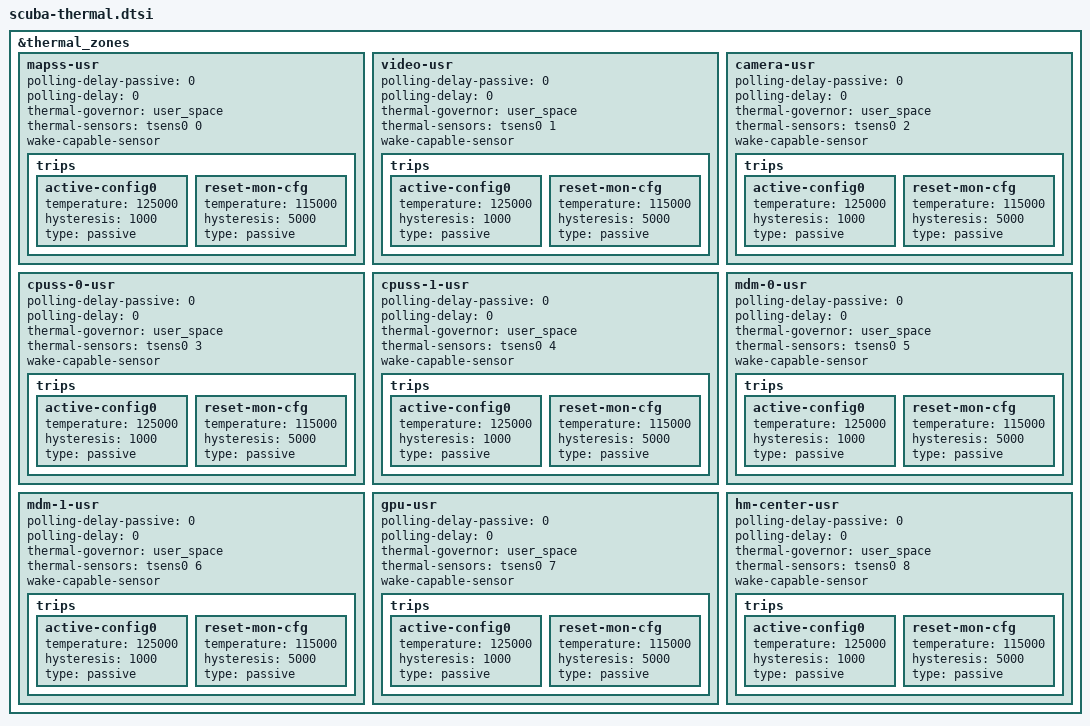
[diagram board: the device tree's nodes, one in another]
# include <dt-bindings/thermal/thermal.h>

&thermal_zones {
	mapss-usr {
		polling-delay-passive = <0>;
		polling-delay = <0>;
		thermal-governor = "user_space";
		thermal-sensors = <&tsens0 0>;
		wake-capable-sensor;
		trips {
			active-config0 {
				temperature = <125000>;
				hysteresis = <1000>;
				type = "passive";
			};

			reset-mon-cfg {
				temperature = <115000>;
				hysteresis = <5000>;
				type = "passive";
			};
		};
	};

	video-usr {
		polling-delay-passive = <0>;
		polling-delay = <0>;
		thermal-governor = "user_space";
		thermal-sensors = <&tsens0 1>;
		wake-capable-sensor;
		trips {
			active-config0 {
				temperature = <125000>;
				hysteresis = <1000>;
				type = "passive";
			};

			reset-mon-cfg {
				temperature = <115000>;
				hysteresis = <5000>;
				type = "passive";
			};
		};
	};

	camera-usr {
		polling-delay-passive = <0>;
		polling-delay = <0>;
		thermal-governor = "user_space";
		thermal-sensors = <&tsens0 2>;
		wake-capable-sensor;
		trips {
			active-config0 {
				temperature = <125000>;
				hysteresis = <1000>;
				type = "passive";
			};

			reset-mon-cfg {
				temperature = <115000>;
				hysteresis = <5000>;
				type = "passive";
			};
		};
	};

	cpuss-0-usr {
		polling-delay-passive = <0>;
		polling-delay = <0>;
		thermal-governor = "user_space";
		thermal-sensors = <&tsens0 3>;
		wake-capable-sensor;
		trips {
			active-config0 {
				temperature = <125000>;
				hysteresis = <1000>;
				type = "passive";
			};

			reset-mon-cfg {
				temperature = <115000>;
				hysteresis = <5000>;
				type = "passive";
			};
		};
	};

	cpuss-1-usr {
		polling-delay-passive = <0>;
		polling-delay = <0>;
		thermal-governor = "user_space";
		thermal-sensors = <&tsens0 4>;
		wake-capable-sensor;
		trips {
			active-config0 {
				temperature = <125000>;
				hysteresis = <1000>;
				type = "passive";
			};

			reset-mon-cfg {
				temperature = <115000>;
				hysteresis = <5000>;
				type = "passive";
			};
		};
	};

	mdm-0-usr {
		polling-delay-passive = <0>;
		polling-delay = <0>;
		thermal-governor = "user_space";
		thermal-sensors = <&tsens0 5>;
		wake-capable-sensor;
		trips {
			active-config0 {
				temperature = <125000>;
				hysteresis = <1000>;
				type = "passive";
			};

			reset-mon-cfg {
				temperature = <115000>;
				hysteresis = <5000>;
				type = "passive";
			};
		};
	};

	mdm-1-usr {
		polling-delay-passive = <0>;
		polling-delay = <0>;
		thermal-governor = "user_space";
		thermal-sensors = <&tsens0 6>;
		wake-capable-sensor;
		trips {
			active-config0 {
				temperature = <125000>;
				hysteresis = <1000>;
				type = "passive";
			};

			reset-mon-cfg {
				temperature = <115000>;
				hysteresis = <5000>;
				type = "passive";
			};
		};
	};

	gpu-usr {
		polling-delay-passive = <0>;
		polling-delay = <0>;
		thermal-governor = "user_space";
		thermal-sensors = <&tsens0 7>;
		wake-capable-sensor;
		trips {
			active-config0 {
				temperature = <125000>;
				hysteresis = <1000>;
				type = "passive";
			};

			reset-mon-cfg {
				temperature = <115000>;
				hysteresis = <5000>;
				type = "passive";
			};
		};
	};

	hm-center-usr {
		polling-delay-passive = <0>;
		polling-delay = <0>;
		thermal-governor = "user_space";
		thermal-sensors = <&tsens0 8>;
		wake-capable-sensor;
		trips {
			active-config0 {
				temperature = <125000>;
				hysteresis = <1000>;
				type = "passive";
			};

			reset-mon-cfg {
				temperature = <115000>;
				hysteresis = <5000>;
				type = "passive";
			};
		};
	};
};

